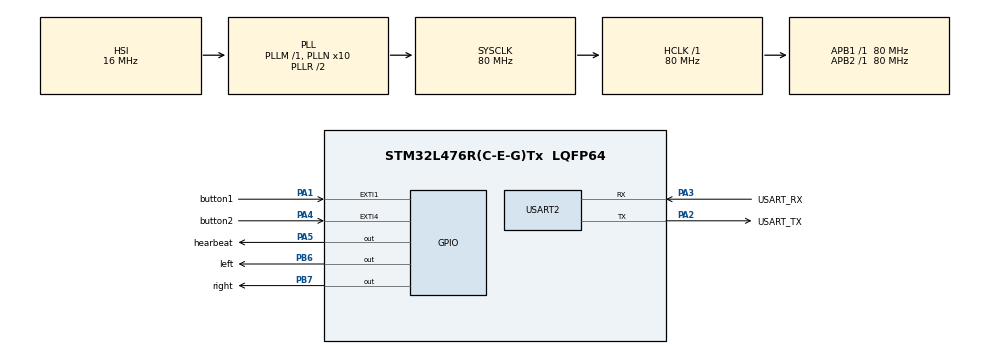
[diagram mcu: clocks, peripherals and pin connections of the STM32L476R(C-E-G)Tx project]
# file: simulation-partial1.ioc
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Mcu.Family=STM32L4
Mcu.Name=STM32L476R(C-E-G)Tx
Mcu.Package=LQFP64
NVIC.PriorityGroup=NVIC_PRIORITYGROUP_4
PA1.GPIO_Label=button1
PA1.Signal=GPXTI1
PA13\ (JTMS-SWDIO).GPIO_Label=TMS
PA13\ (JTMS-SWDIO).Mode=Serial_Wire
PA13\ (JTMS-SWDIO).Signal=SYS_JTMS-SWDIO
PA14\ (JTCK-SWCLK).GPIO_Label=TCK
PA14\ (JTCK-SWCLK).Mode=Serial_Wire
PA14\ (JTCK-SWCLK).Signal=SYS_JTCK-SWCLK
PA2.GPIO_Label=USART_TX
PA2.GPIO_Mode=GPIO_MODE_AF_PP
PA2.GPIO_PuPd=GPIO_NOPULL
PA2.GPIO_Speed=GPIO_SPEED_FREQ_VERY_HIGH
PA2.Mode=Asynchronous
PA2.Signal=USART2_TX
PA3.GPIO_Label=USART_RX
PA3.GPIO_Mode=GPIO_MODE_AF_PP
PA3.GPIO_PuPd=GPIO_NOPULL
PA3.GPIO_Speed=GPIO_SPEED_FREQ_VERY_HIGH
PA3.Mode=Asynchronous
PA3.Signal=USART2_RX
PA4.GPIO_Label=button2
PA4.Signal=GPXTI4
PA5.GPIO_Label=hearbeat
PA5.Signal=GPIO_Output
PB3\ (JTDO-TRACESWO).GPIO_Label=SWO
PB3\ (JTDO-TRACESWO).Signal=SYS_JTDO-SWO
PB6.GPIO_Label=left
PB6.Signal=GPIO_Output
PB7.GPIO_Label=right
PB7.Signal=GPIO_Output
PC14-OSC32_IN\ (PC14).Mode=LSE-External-Oscillator
PC14-OSC32_IN\ (PC14).Signal=RCC_OSC32_IN
PC15-OSC32_OUT\ (PC15).Mode=LSE-External-Oscillator
PC15-OSC32_OUT\ (PC15).Signal=RCC_OSC32_OUT
PH0-OSC_IN\ (PH0).Signal=RCC_OSC_IN
PH1-OSC_OUT\ (PH1).Signal=RCC_OSC_OUT
ProjectManager.HeapSize=0x200
ProjectManager.StackSize=0x400
ProjectManager.TargetToolchain=STM32CubeIDE
RCC.ADCFreq_Value=64000000
RCC.AHBFreq_Value=80000000
RCC.APB1Freq_Value=80000000
RCC.APB1TimFreq_Value=80000000
RCC.APB2Freq_Value=80000000
RCC.APB2TimFreq_Value=80000000
RCC.CortexFreq_Value=80000000
RCC.HCLKFreq_Value=80000000
RCC.HSE_VALUE=8000000
RCC.HSI_VALUE=16000000
RCC.MSI_VALUE=4000000
RCC.PLLN=10
RCC.PLLSourceVirtual=RCC_PLLSOURCE_HSI
RCC.PREFETCH_ENABLE=1
RCC.SYSCLKFreq_VALUE=80000000
RCC.SYSCLKSource=RCC_SYSCLKSOURCE_PLLCLK
RCC.USBFreq_Value=64000000
RCC.VCOOutputFreq_Value=160000000
USART2.VirtualMode-Asynchronous=VM_ASYNC
board=NUCLEO-L476RG

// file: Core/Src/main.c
/* USER CODE BEGIN Header */
/**
  ******************************************************************************
  * @file           : main.c
  * @brief          : Main program body
  ******************************************************************************
  * @attention
  *
  * Copyright (c) 2024 STMicroelectronics.
  * All rights reserved.
  *
  * This software is licensed under terms that can be found in the LICENSE file
  * in the root directory of this software component.
  * If no LICENSE file comes with this software, it is provided AS-IS.
  *
  ******************************************************************************
  */
/* USER CODE END Header */
#include "main.h"

UART_HandleTypeDef huart2;

/* USER CODE BEGIN PV */
uint32_t left_toggles = 0;
uint32_t left_last_press_tick = 0;
/* USER CODE END PV */

void SystemClock_Config(void);
static void MX_GPIO_Init(void);
static void MX_USART2_UART_Init(void);
void hearbeat(void);
void HAL_GPIO_EXTI_Callback(uint16_t GPIO_Pin)
{
	if (GPIO_Pin == left_Pin) {
		HAL_UART_Transmit(&huart2, "left\r\n", 6, 10);
		if (HAL_GetTick() < (left_last_press_tick + 300)) { // if last press was in the last 300ms
			left_toggles = 0xFFFFFF; // a long time toggling (infinite)
		} else {
			left_toggles = 3;
		}
		left_last_press_tick = HAL_GetTick();
	} else if (GPIO_Pin == left_Pin) {
		left_toggles = 0;
	}
}
void hearbeat(void)
{
	static uint32_t heartbeat_tick = 0;
	if (heartbeat_tick < HAL_GetTick()) {
		heartbeat_tick = HAL_GetTick() + 500;
		HAL_GPIO_TogglePin(hearbeat_GPIO_Port, hearbeat_Pin);
	}
}
void turn_signal_left(void)
{
	static uint32_t turn_toggle_tick = 0;
	if (turn_toggle_tick < HAL_GetTick()) {
		if (left_toggles > 0) {
			turn_toggle_tick = HAL_GetTick() + 500;
			HAL_GPIO_TogglePin(left_GPIO_Port, left_Pin);
			left_toggles--;
		} else {
			HAL_GPIO_WritePin(left_GPIO_Port, left_Pin, 1);
		}

	}
}

int main(void)
{

  /* MCU Configuration--------------------------------------------------------*/

  /* Reset of all peripherals, Initializes the Flash interface and the Systick. */
  HAL_Init();

  /* Configure the system clock */
  SystemClock_Config();

  /* Initialize all configured peripherals */
  MX_GPIO_Init();
  MX_USART2_UART_Init();

  /* Infinite loop */
  /* USER CODE BEGIN WHILE */
  while (1)
  {
	  hearbeat();
	  turn_signal_left();
    /* USER CODE END WHILE */

  }
}

void SystemClock_Config(void)
{
  RCC_OscInitTypeDef RCC_OscInitStruct = {0};
  RCC_ClkInitTypeDef RCC_ClkInitStruct = {0};

  /** Configure the main internal regulator output voltage
  */
  if (HAL_PWREx_ControlVoltageScaling(PWR_REGULATOR_VOLTAGE_SCALE1) != HAL_OK)
  {
    Error_Handler();
  }

  /** Initializes the RCC Oscillators according to the specified parameters
  * in the RCC_OscInitTypeDef structure.
  */
  RCC_OscInitStruct.OscillatorType = RCC_OSCILLATORTYPE_HSI;
  RCC_OscInitStruct.HSIState = RCC_HSI_ON;
  RCC_OscInitStruct.HSICalibrationValue = RCC_HSICALIBRATION_DEFAULT;
  RCC_OscInitStruct.PLL.PLLState = RCC_PLL_ON;
  RCC_OscInitStruct.PLL.PLLSource = RCC_PLLSOURCE_HSI;
  RCC_OscInitStruct.PLL.PLLM = 1;
  RCC_OscInitStruct.PLL.PLLN = 10;
  RCC_OscInitStruct.PLL.PLLP = RCC_PLLP_DIV7;
  RCC_OscInitStruct.PLL.PLLQ = RCC_PLLQ_DIV2;
  RCC_OscInitStruct.PLL.PLLR = RCC_PLLR_DIV2;
  if (HAL_RCC_OscConfig(&RCC_OscInitStruct) != HAL_OK)
  {
    Error_Handler();
  }

  /** Initializes the CPU, AHB and APB buses clocks
  */
  RCC_ClkInitStruct.ClockType = RCC_CLOCKTYPE_HCLK|RCC_CLOCKTYPE_SYSCLK
                              |RCC_CLOCKTYPE_PCLK1|RCC_CLOCKTYPE_PCLK2;
  RCC_ClkInitStruct.SYSCLKSource = RCC_SYSCLKSOURCE_PLLCLK;
  RCC_ClkInitStruct.AHBCLKDivider = RCC_SYSCLK_DIV1;
  RCC_ClkInitStruct.APB1CLKDivider = RCC_HCLK_DIV1;
  RCC_ClkInitStruct.APB2CLKDivider = RCC_HCLK_DIV1;

  if (HAL_RCC_ClockConfig(&RCC_ClkInitStruct, FLASH_LATENCY_4) != HAL_OK)
  {
    Error_Handler();
  }
}

static void MX_USART2_UART_Init(void)
{

  huart2.Instance = USART2;
  huart2.Init.BaudRate = 115200;
  huart2.Init.WordLength = UART_WORDLENGTH_8B;
  huart2.Init.StopBits = UART_STOPBITS_1;
  huart2.Init.Parity = UART_PARITY_NONE;
  huart2.Init.Mode = UART_MODE_TX_RX;
  huart2.Init.HwFlowCtl = UART_HWCONTROL_NONE;
  huart2.Init.OverSampling = UART_OVERSAMPLING_16;
  huart2.Init.OneBitSampling = UART_ONE_BIT_SAMPLE_DISABLE;
  huart2.AdvancedInit.AdvFeatureInit = UART_ADVFEATURE_NO_INIT;
  if (HAL_UART_Init(&huart2) != HAL_OK)
  {
    Error_Handler();
  }

}

static void MX_GPIO_Init(void)
{
  GPIO_InitTypeDef GPIO_InitStruct = {0};

  /* GPIO Ports Clock Enable */
  __HAL_RCC_GPIOC_CLK_ENABLE();
  __HAL_RCC_GPIOH_CLK_ENABLE();
  __HAL_RCC_GPIOA_CLK_ENABLE();
  __HAL_RCC_GPIOB_CLK_ENABLE();

  /*Configure GPIO pin Output Level */
  HAL_GPIO_WritePin(hearbeat_GPIO_Port, hearbeat_Pin, GPIO_PIN_RESET);

  /*Configure GPIO pin Output Level */
  HAL_GPIO_WritePin(GPIOB, left_Pin|right_Pin, GPIO_PIN_RESET);

  /*Configure GPIO pins : button1_Pin button2_Pin */
  GPIO_InitStruct.Pin = button1_Pin|button2_Pin;
  GPIO_InitStruct.Mode = GPIO_MODE_IT_RISING;
  GPIO_InitStruct.Pull = GPIO_NOPULL;
  HAL_GPIO_Init(GPIOA, &GPIO_InitStruct);

  /*Configure GPIO pin : hearbeat_Pin */
  GPIO_InitStruct.Pin = hearbeat_Pin;
  GPIO_InitStruct.Mode = GPIO_MODE_OUTPUT_PP;
  GPIO_InitStruct.Pull = GPIO_NOPULL;
  GPIO_InitStruct.Speed = GPIO_SPEED_FREQ_LOW;
  HAL_GPIO_Init(hearbeat_GPIO_Port, &GPIO_InitStruct);

  /*Configure GPIO pins : left_Pin right_Pin */
  GPIO_InitStruct.Pin = left_Pin|right_Pin;
  GPIO_InitStruct.Mode = GPIO_MODE_OUTPUT_PP;
  GPIO_InitStruct.Pull = GPIO_NOPULL;
  GPIO_InitStruct.Speed = GPIO_SPEED_FREQ_LOW;
  HAL_GPIO_Init(GPIOB, &GPIO_InitStruct);

}

void Error_Handler(void)
{
  __disable_irq();
  while (1)
  {
  }
}
